# MCU_ECC_AGGR0_ECC_AGGR register map
Vendor: Texas Instruments
Peripheral module from a debugger description file (folder am65x).
Registers are 32-bit, access not given, reset 0x0 unless marked. A register's access mark holds for its fields unless they carry their own. Offsets are as the file gives them; lines under a group give offsets from that group; [hi:lo] are bit positions; {n}, {i} and the like mark numbered series; 'fields as' and 'values as' point back to an identical list; <NAME> marks a mode.

## MCU_ECC_AGGR0_ECC_AGGR
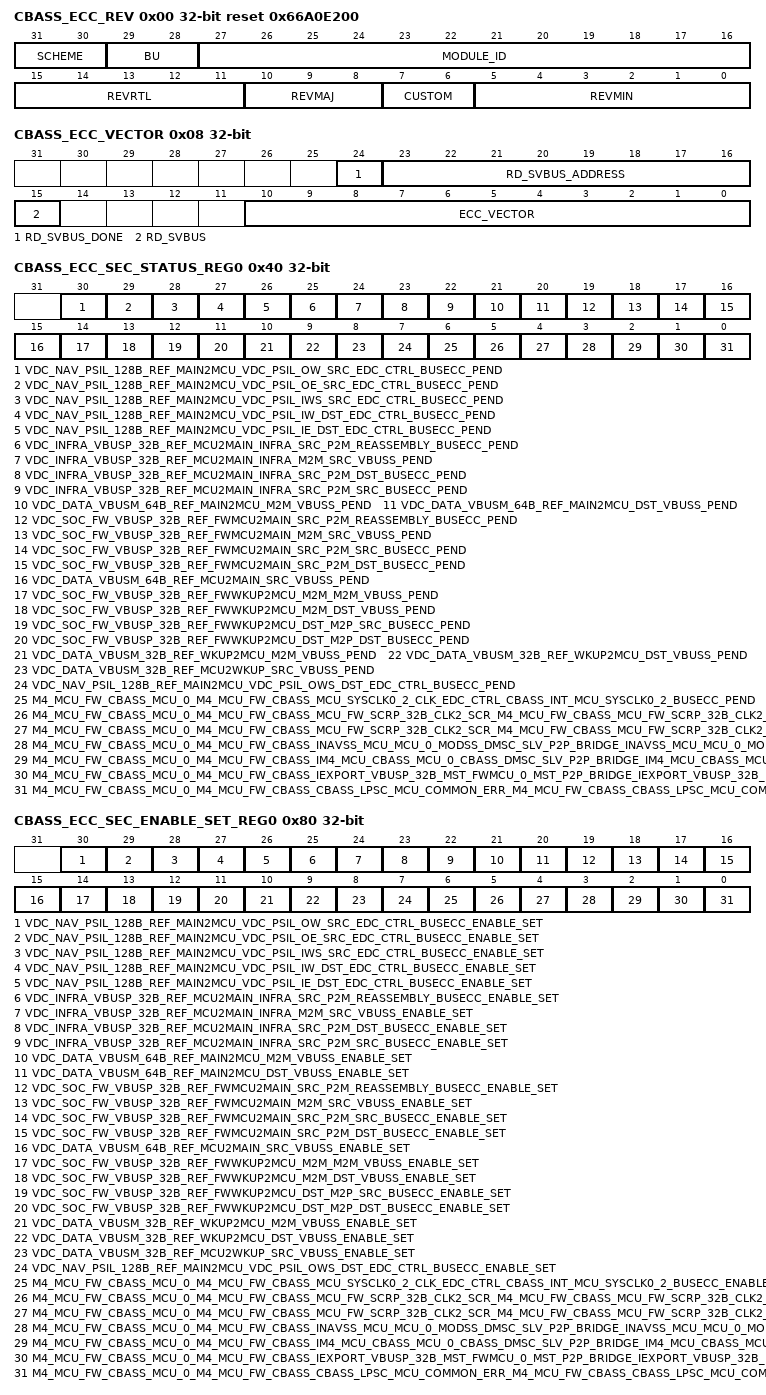
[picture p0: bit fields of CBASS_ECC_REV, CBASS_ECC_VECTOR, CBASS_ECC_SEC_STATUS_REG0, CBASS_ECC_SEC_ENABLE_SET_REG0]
0x00 CBASS_ECC_REV ro reset 0x66A0E200 — Return to the . Revision parameters
  [31:30] SCHEME
  [29:28] BU
  [27:16] MODULE_ID
  [15:11] REVRTL — RTL version
  [10:8] REVMAJ — Major version
  [7:6] CUSTOM — Custom version
  [5:0] REVMIN — Minor version
0x08 CBASS_ECC_VECTOR — Return to the . ECC Vector Register
  [24] RD_SVBUS_DONE — Status to indicate if read on serial VBUS is complete, write of any value will clear this bit. (access RW1C)
  [23:16] RD_SVBUS_ADDRESS rw — Read address
  [15] RD_SVBUS — Write 1 to trigger a read on the serial VBUS (access RW1S)
  [10:0] ECC_VECTOR rw — Value written to select the corresponding ECC RAM for control or status
0x0C CBASS_ECC_STAT ro reset 0x1F — Return to the . Misc Status
  [10:0] NUM_RAMS — Indicates the number of RAMS serviced by the ECC aggregator
0x3C CBASS_ECC_SEC_EOI_REG — Return to the . EOI Register
  [0] EOI_WR — EOI Register (access RW1S)
0x40 CBASS_ECC_SEC_STATUS_REG0 — Return to the . Interrupt Status Register 0
  [30] VDC_NAV_PSIL_128B_REF_MAIN2MCU_VDC_PSIL_OW_SRC_EDC_CTRL_BUSECC_PEND — Interrupt Pending Status for vdc_nav_psil_128b_ref_main2mcu_vdc_psil_ow_src_edc_ctrl_busecc__pend (access RW1S)
  [29] VDC_NAV_PSIL_128B_REF_MAIN2MCU_VDC_PSIL_OE_SRC_EDC_CTRL_BUSECC_PEND — Interrupt Pending Status for vdc_nav_psil_128b_ref_main2mcu_vdc_psil_oe_src_edc_ctrl_busecc__pend (access RW1S)
  [28] VDC_NAV_PSIL_128B_REF_MAIN2MCU_VDC_PSIL_IWS_SRC_EDC_CTRL_BUSECC_PEND — Interrupt Pending Status for vdc_nav_psil_128b_ref_main2mcu_vdc_psil_iws_src_edc_ctrl_busecc__pend (access RW1S)
  [27] VDC_NAV_PSIL_128B_REF_MAIN2MCU_VDC_PSIL_IW_DST_EDC_CTRL_BUSECC_PEND — Interrupt Pending Status for vdc_nav_psil_128b_ref_main2mcu_vdc_psil_iw_dst_edc_ctrl_busecc__pend (access RW1S)
  [26] VDC_NAV_PSIL_128B_REF_MAIN2MCU_VDC_PSIL_IE_DST_EDC_CTRL_BUSECC_PEND — Interrupt Pending Status for vdc_nav_psil_128b_ref_main2mcu_vdc_psil_ie_dst_edc_ctrl_busecc__pend (access RW1S)
  [25] VDC_INFRA_VBUSP_32B_REF_MCU2MAIN_INFRA_SRC_P2M_REASSEMBLY_BUSECC_PEND — Interrupt Pending Status for vdc_infra_vbusp_32b_ref_mcu2main_infra_src_p2m_reassembly_busecc__pend (access RW1S)
  [24] VDC_INFRA_VBUSP_32B_REF_MCU2MAIN_INFRA_M2M_SRC_VBUSS_PEND — Interrupt Pending Status for vdc_infra_vbusp_32b_ref_mcu2main_infra_m2m_src_vbuss__pend (access RW1S)
  [23] VDC_INFRA_VBUSP_32B_REF_MCU2MAIN_INFRA_SRC_P2M_DST_BUSECC_PEND — Interrupt Pending Status for vdc_infra_vbusp_32b_ref_mcu2main_infra_src_p2m_dst_busecc__pend (access RW1S)
  [22] VDC_INFRA_VBUSP_32B_REF_MCU2MAIN_INFRA_SRC_P2M_SRC_BUSECC_PEND — Interrupt Pending Status for vdc_infra_vbusp_32b_ref_mcu2main_infra_src_p2m_src_busecc__pend (access RW1S)
  [21] VDC_DATA_VBUSM_64B_REF_MAIN2MCU_M2M_VBUSS_PEND — Interrupt Pending Status for vdc_data_vbusm_64b_ref_main2mcu_m2m_vbuss__pend (access RW1S)
  [20] VDC_DATA_VBUSM_64B_REF_MAIN2MCU_DST_VBUSS_PEND — Interrupt Pending Status for vdc_data_vbusm_64b_ref_main2mcu_dst_vbuss__pend (access RW1S)
  [19] VDC_SOC_FW_VBUSP_32B_REF_FWMCU2MAIN_SRC_P2M_REASSEMBLY_BUSECC_PEND — Interrupt Pending Status for vdc_soc_fw_vbusp_32b_ref_fwmcu2main_src_p2m_reassembly_busecc__pend (access RW1S)
  [18] VDC_SOC_FW_VBUSP_32B_REF_FWMCU2MAIN_M2M_SRC_VBUSS_PEND — Interrupt Pending Status for vdc_soc_fw_vbusp_32b_ref_fwmcu2main_m2m_src_vbuss__pend (access RW1S)
  [17] VDC_SOC_FW_VBUSP_32B_REF_FWMCU2MAIN_SRC_P2M_SRC_BUSECC_PEND — Interrupt Pending Status for vdc_soc_fw_vbusp_32b_ref_fwmcu2main_src_p2m_src_busecc__pend (access RW1S)
  [16] VDC_SOC_FW_VBUSP_32B_REF_FWMCU2MAIN_SRC_P2M_DST_BUSECC_PEND — Interrupt Pending Status for vdc_soc_fw_vbusp_32b_ref_fwmcu2main_src_p2m_dst_busecc__pend (access RW1S)
  [15] VDC_DATA_VBUSM_64B_REF_MCU2MAIN_SRC_VBUSS_PEND — Interrupt Pending Status for vdc_data_vbusm_64b_ref_mcu2main_src_vbuss__pend (access RW1S)
  [14] VDC_SOC_FW_VBUSP_32B_REF_FWWKUP2MCU_M2M_M2M_VBUSS_PEND — Interrupt Pending Status for vdc_soc_fw_vbusp_32b_ref_fwwkup2mcu_m2m_m2m_vbuss__pend (access RW1S)
  [13] VDC_SOC_FW_VBUSP_32B_REF_FWWKUP2MCU_M2M_DST_VBUSS_PEND — Interrupt Pending Status for vdc_soc_fw_vbusp_32b_ref_fwwkup2mcu_m2m_dst_vbuss__pend (access RW1S)
  [12] VDC_SOC_FW_VBUSP_32B_REF_FWWKUP2MCU_DST_M2P_SRC_BUSECC_PEND — Interrupt Pending Status for vdc_soc_fw_vbusp_32b_ref_fwwkup2mcu_dst_m2p_src_busecc__pend (access RW1S)
  [11] VDC_SOC_FW_VBUSP_32B_REF_FWWKUP2MCU_DST_M2P_DST_BUSECC_PEND — Interrupt Pending Status for vdc_soc_fw_vbusp_32b_ref_fwwkup2mcu_dst_m2p_dst_busecc__pend (access RW1S)
  [10] VDC_DATA_VBUSM_32B_REF_WKUP2MCU_M2M_VBUSS_PEND — Interrupt Pending Status for vdc_data_vbusm_32b_ref_wkup2mcu_m2m_vbuss__pend (access RW1S)
  [9] VDC_DATA_VBUSM_32B_REF_WKUP2MCU_DST_VBUSS_PEND — Interrupt Pending Status for vdc_data_vbusm_32b_ref_wkup2mcu_dst_vbuss__pend (access RW1S)
  [8] VDC_DATA_VBUSM_32B_REF_MCU2WKUP_SRC_VBUSS_PEND — Interrupt Pending Status for vdc_data_vbusm_32b_ref_mcu2wkup_src_vbuss__pend (access RW1S)
  [7] VDC_NAV_PSIL_128B_REF_MAIN2MCU_VDC_PSIL_OWS_DST_EDC_CTRL_BUSECC_PEND — Interrupt Pending Status for vdc_nav_psil_128b_ref_main2mcu_vdc_psil_ows_dst_edc_ctrl_busecc__pend (access RW1S)
  [6] M4_MCU_FW_CBASS_MCU_0_M4_MCU_FW_CBASS_MCU_SYSCLK0_2_CLK_EDC_CTRL_CBASS_INT_MCU_SYSCLK0_2_BUSECC_PEND — Interrupt Pending Status for m4_mcu_fw_cbass_mcu_0_m4_mcu_fw_cbass_mcu_sysclk0_2_clk_edc_ctrl_cbass_int_mcu_sysclk0_2_busecc__pend (access RW1S)
  [5] M4_MCU_FW_CBASS_MCU_0_M4_MCU_FW_CBASS_MCU_FW_SCRP_32B_CLK2_SCR_M4_MCU_FW_CBASS_MCU_FW_SCRP_32B_CLK2_SCR_EDC_CTRL_BUSECC_1_PEND — Interrupt Pending Status for m4_mcu_fw_cbass_mcu_0_m4_mcu_fw_cbass_MCU_FW_SCRP_32b_CLK2_scr_m4_mcu_fw_cbass_MCU_FW_SCRP_32b_CLK2_scr_edc_ctrl_busecc_1__pend (access RW1S)
  [4] M4_MCU_FW_CBASS_MCU_0_M4_MCU_FW_CBASS_MCU_FW_SCRP_32B_CLK2_SCR_M4_MCU_FW_CBASS_MCU_FW_SCRP_32B_CLK2_SCR_EDC_CTRL_BUSECC_0_PEND — Interrupt Pending Status for m4_mcu_fw_cbass_mcu_0_m4_mcu_fw_cbass_MCU_FW_SCRP_32b_CLK2_scr_m4_mcu_fw_cbass_MCU_FW_SCRP_32b_CLK2_scr_edc_ctrl_busecc_0__pend (access RW1S)
  [3] M4_MCU_FW_CBASS_MCU_0_M4_MCU_FW_CBASS_INAVSS_MCU_MCU_0_MODSS_DMSC_SLV_P2P_BRIDGE_INAVSS_MCU_MCU_0_MODSS_DMSC_SLV_BRIDGE_BUSECC_PEND — Interrupt Pending Status for m4_mcu_fw_cbass_mcu_0_m4_mcu_fw_cbass_Inavss_mcu_mcu_0_modss_dmsc_slv_p2p_bridge_Inavss_mcu_mcu_0_modss_dmsc_slv_bridge_busecc__pend (access RW1S)
  [2] M4_MCU_FW_CBASS_MCU_0_M4_MCU_FW_CBASS_IM4_MCU_CBASS_MCU_0_CBASS_DMSC_SLV_P2P_BRIDGE_IM4_MCU_CBASS_MCU_0_CBASS_DMSC_SLV_BRIDGE_BUSECC_PEND — Interrupt Pending Status for m4_mcu_fw_cbass_mcu_0_m4_mcu_fw_cbass_Im4_mcu_cbass_mcu_0_cbass_dmsc_slv_p2p_bridge_Im4_mcu_cbass_mcu_0_cbass_dmsc_slv_bridge_busecc__pend (access RW1S)
  [1] M4_MCU_FW_CBASS_MCU_0_M4_MCU_FW_CBASS_IEXPORT_VBUSP_32B_MST_FWMCU_0_MST_P2P_BRIDGE_IEXPORT_VBUSP_32B_MST_FWMCU_0_MST_BRIDGE_BUSECC_PEND — Interrupt Pending Status for m4_mcu_fw_cbass_mcu_0_m4_mcu_fw_cbass_Iexport_vbusp_32b_mst_fwmcu_0_mst_p2p_bridge_Iexport_vbusp_32b_mst_fwmcu_0_mst_bridge_busecc__pend (access RW1S)
  [0] M4_MCU_FW_CBASS_MCU_0_M4_MCU_FW_CBASS_CBASS_LPSC_MCU_COMMON_ERR_M4_MCU_FW_CBASS_CBASS_LPSC_MCU_COMMON_ERR_EDC_CTRL_BUSECC_PEND — Interrupt Pending Status for m4_mcu_fw_cbass_mcu_0_m4_mcu_fw_cbass_cbass_LPSC_MCU_common_err_m4_mcu_fw_cbass_cbass_LPSC_MCU_common_err_edc_ctrl_busecc__pend (access RW1S)
0x80 CBASS_ECC_SEC_ENABLE_SET_REG0 — Return to the . Interrupt Enable Set Register 0
  [30] VDC_NAV_PSIL_128B_REF_MAIN2MCU_VDC_PSIL_OW_SRC_EDC_CTRL_BUSECC_ENABLE_SET — Interrupt Enable Set Register for vdc_nav_psil_128b_ref_main2mcu_vdc_psil_ow_src_edc_ctrl_busecc__pend (access RW1S)
  [29] VDC_NAV_PSIL_128B_REF_MAIN2MCU_VDC_PSIL_OE_SRC_EDC_CTRL_BUSECC_ENABLE_SET — Interrupt Enable Set Register for vdc_nav_psil_128b_ref_main2mcu_vdc_psil_oe_src_edc_ctrl_busecc__pend (access RW1S)
  [28] VDC_NAV_PSIL_128B_REF_MAIN2MCU_VDC_PSIL_IWS_SRC_EDC_CTRL_BUSECC_ENABLE_SET — Interrupt Enable Set Register for vdc_nav_psil_128b_ref_main2mcu_vdc_psil_iws_src_edc_ctrl_busecc__pend (access RW1S)
  [27] VDC_NAV_PSIL_128B_REF_MAIN2MCU_VDC_PSIL_IW_DST_EDC_CTRL_BUSECC_ENABLE_SET — Interrupt Enable Set Register for vdc_nav_psil_128b_ref_main2mcu_vdc_psil_iw_dst_edc_ctrl_busecc__pend (access RW1S)
  [26] VDC_NAV_PSIL_128B_REF_MAIN2MCU_VDC_PSIL_IE_DST_EDC_CTRL_BUSECC_ENABLE_SET — Interrupt Enable Set Register for vdc_nav_psil_128b_ref_main2mcu_vdc_psil_ie_dst_edc_ctrl_busecc__pend (access RW1S)
  [25] VDC_INFRA_VBUSP_32B_REF_MCU2MAIN_INFRA_SRC_P2M_REASSEMBLY_BUSECC_ENABLE_SET — Interrupt Enable Set Register for vdc_infra_vbusp_32b_ref_mcu2main_infra_src_p2m_reassembly_busecc__pend (access RW1S)
  [24] VDC_INFRA_VBUSP_32B_REF_MCU2MAIN_INFRA_M2M_SRC_VBUSS_ENABLE_SET — Interrupt Enable Set Register for vdc_infra_vbusp_32b_ref_mcu2main_infra_m2m_src_vbuss__pend (access RW1S)
  [23] VDC_INFRA_VBUSP_32B_REF_MCU2MAIN_INFRA_SRC_P2M_DST_BUSECC_ENABLE_SET — Interrupt Enable Set Register for vdc_infra_vbusp_32b_ref_mcu2main_infra_src_p2m_dst_busecc__pend (access RW1S)
  [22] VDC_INFRA_VBUSP_32B_REF_MCU2MAIN_INFRA_SRC_P2M_SRC_BUSECC_ENABLE_SET — Interrupt Enable Set Register for vdc_infra_vbusp_32b_ref_mcu2main_infra_src_p2m_src_busecc__pend (access RW1S)
  [21] VDC_DATA_VBUSM_64B_REF_MAIN2MCU_M2M_VBUSS_ENABLE_SET — Interrupt Enable Set Register for vdc_data_vbusm_64b_ref_main2mcu_m2m_vbuss__pend (access RW1S)
  [20] VDC_DATA_VBUSM_64B_REF_MAIN2MCU_DST_VBUSS_ENABLE_SET — Interrupt Enable Set Register for vdc_data_vbusm_64b_ref_main2mcu_dst_vbuss__pend (access RW1S)
  [19] VDC_SOC_FW_VBUSP_32B_REF_FWMCU2MAIN_SRC_P2M_REASSEMBLY_BUSECC_ENABLE_SET — Interrupt Enable Set Register for vdc_soc_fw_vbusp_32b_ref_fwmcu2main_src_p2m_reassembly_busecc__pend (access RW1S)
  [18] VDC_SOC_FW_VBUSP_32B_REF_FWMCU2MAIN_M2M_SRC_VBUSS_ENABLE_SET — Interrupt Enable Set Register for vdc_soc_fw_vbusp_32b_ref_fwmcu2main_m2m_src_vbuss__pend (access RW1S)
  [17] VDC_SOC_FW_VBUSP_32B_REF_FWMCU2MAIN_SRC_P2M_SRC_BUSECC_ENABLE_SET — Interrupt Enable Set Register for vdc_soc_fw_vbusp_32b_ref_fwmcu2main_src_p2m_src_busecc__pend (access RW1S)
  [16] VDC_SOC_FW_VBUSP_32B_REF_FWMCU2MAIN_SRC_P2M_DST_BUSECC_ENABLE_SET — Interrupt Enable Set Register for vdc_soc_fw_vbusp_32b_ref_fwmcu2main_src_p2m_dst_busecc__pend (access RW1S)
  [15] VDC_DATA_VBUSM_64B_REF_MCU2MAIN_SRC_VBUSS_ENABLE_SET — Interrupt Enable Set Register for vdc_data_vbusm_64b_ref_mcu2main_src_vbuss__pend (access RW1S)
  [14] VDC_SOC_FW_VBUSP_32B_REF_FWWKUP2MCU_M2M_M2M_VBUSS_ENABLE_SET — Interrupt Enable Set Register for vdc_soc_fw_vbusp_32b_ref_fwwkup2mcu_m2m_m2m_vbuss__pend (access RW1S)
  [13] VDC_SOC_FW_VBUSP_32B_REF_FWWKUP2MCU_M2M_DST_VBUSS_ENABLE_SET — Interrupt Enable Set Register for vdc_soc_fw_vbusp_32b_ref_fwwkup2mcu_m2m_dst_vbuss__pend (access RW1S)
  [12] VDC_SOC_FW_VBUSP_32B_REF_FWWKUP2MCU_DST_M2P_SRC_BUSECC_ENABLE_SET — Interrupt Enable Set Register for vdc_soc_fw_vbusp_32b_ref_fwwkup2mcu_dst_m2p_src_busecc__pend (access RW1S)
  [11] VDC_SOC_FW_VBUSP_32B_REF_FWWKUP2MCU_DST_M2P_DST_BUSECC_ENABLE_SET — Interrupt Enable Set Register for vdc_soc_fw_vbusp_32b_ref_fwwkup2mcu_dst_m2p_dst_busecc__pend (access RW1S)
  [10] VDC_DATA_VBUSM_32B_REF_WKUP2MCU_M2M_VBUSS_ENABLE_SET — Interrupt Enable Set Register for vdc_data_vbusm_32b_ref_wkup2mcu_m2m_vbuss__pend (access RW1S)
  [9] VDC_DATA_VBUSM_32B_REF_WKUP2MCU_DST_VBUSS_ENABLE_SET — Interrupt Enable Set Register for vdc_data_vbusm_32b_ref_wkup2mcu_dst_vbuss__pend (access RW1S)
  [8] VDC_DATA_VBUSM_32B_REF_MCU2WKUP_SRC_VBUSS_ENABLE_SET — Interrupt Enable Set Register for vdc_data_vbusm_32b_ref_mcu2wkup_src_vbuss__pend (access RW1S)
  [7] VDC_NAV_PSIL_128B_REF_MAIN2MCU_VDC_PSIL_OWS_DST_EDC_CTRL_BUSECC_ENABLE_SET — Interrupt Enable Set Register for vdc_nav_psil_128b_ref_main2mcu_vdc_psil_ows_dst_edc_ctrl_busecc__pend (access RW1S)
  [6] M4_MCU_FW_CBASS_MCU_0_M4_MCU_FW_CBASS_MCU_SYSCLK0_2_CLK_EDC_CTRL_CBASS_INT_MCU_SYSCLK0_2_BUSECC_ENABLE_SET — Interrupt Enable Set Register for m4_mcu_fw_cbass_mcu_0_m4_mcu_fw_cbass_mcu_sysclk0_2_clk_edc_ctrl_cbass_int_mcu_sysclk0_2_busecc__pend (access RW1S)
  [5] M4_MCU_FW_CBASS_MCU_0_M4_MCU_FW_CBASS_MCU_FW_SCRP_32B_CLK2_SCR_M4_MCU_FW_CBASS_MCU_FW_SCRP_32B_CLK2_SCR_EDC_CTRL_BUSECC_1_ENABLE_SET — Interrupt Enable Set Register for m4_mcu_fw_cbass_mcu_0_m4_mcu_fw_cbass_MCU_FW_SCRP_32b_CLK2_scr_m4_mcu_fw_cbass_MCU_FW_SCRP_32b_CLK2_scr_edc_ctrl_busecc_1__pend (access RW1S)
  [4] M4_MCU_FW_CBASS_MCU_0_M4_MCU_FW_CBASS_MCU_FW_SCRP_32B_CLK2_SCR_M4_MCU_FW_CBASS_MCU_FW_SCRP_32B_CLK2_SCR_EDC_CTRL_BUSECC_0_ENABLE_SET — Interrupt Enable Set Register for m4_mcu_fw_cbass_mcu_0_m4_mcu_fw_cbass_MCU_FW_SCRP_32b_CLK2_scr_m4_mcu_fw_cbass_MCU_FW_SCRP_32b_CLK2_scr_edc_ctrl_busecc_0__pend (access RW1S)
  [3] M4_MCU_FW_CBASS_MCU_0_M4_MCU_FW_CBASS_INAVSS_MCU_MCU_0_MODSS_DMSC_SLV_P2P_BRIDGE_INAVSS_MCU_MCU_0_MODSS_DMSC_SLV_BRIDGE_BUSECC_ENABLE_SET — Interrupt Enable Set Register for m4_mcu_fw_cbass_mcu_0_m4_mcu_fw_cbass_Inavss_mcu_mcu_0_modss_dmsc_slv_p2p_bridge_Inavss_mcu_mcu_0_modss_dmsc_slv_bridge_busecc__pend (access RW1S)
  [2] M4_MCU_FW_CBASS_MCU_0_M4_MCU_FW_CBASS_IM4_MCU_CBASS_MCU_0_CBASS_DMSC_SLV_P2P_BRIDGE_IM4_MCU_CBASS_MCU_0_CBASS_DMSC_SLV_BRIDGE_BUSECC_ENABLE_SET — Interrupt Enable Set Register for m4_mcu_fw_cbass_mcu_0_m4_mcu_fw_cbass_Im4_mcu_cbass_mcu_0_cbass_dmsc_slv_p2p_bridge_Im4_mcu_cbass_mcu_0_cbass_dmsc_slv_bridge_busecc__pend (access RW1S)
  [1] M4_MCU_FW_CBASS_MCU_0_M4_MCU_FW_CBASS_IEXPORT_VBUSP_32B_MST_FWMCU_0_MST_P2P_BRIDGE_IEXPORT_VBUSP_32B_MST_FWMCU_0_MST_BRIDGE_BUSECC_ENABLE_SET — Interrupt Enable Set Register for m4_mcu_fw_cbass_mcu_0_m4_mcu_fw_cbass_Iexport_vbusp_32b_mst_fwmcu_0_mst_p2p_bridge_Iexport_vbusp_32b_mst_fwmcu_0_mst_bridge_busecc__pend (access RW1S)
  [0] M4_MCU_FW_CBASS_MCU_0_M4_MCU_FW_CBASS_CBASS_LPSC_MCU_COMMON_ERR_M4_MCU_FW_CBASS_CBASS_LPSC_MCU_COMMON_ERR_EDC_CTRL_BUSECC_ENABLE_SET — Interrupt Enable Set Register for m4_mcu_fw_cbass_mcu_0_m4_mcu_fw_cbass_cbass_LPSC_MCU_common_err_m4_mcu_fw_cbass_cbass_LPSC_MCU_common_err_edc_ctrl_busecc__pend (access RW1S)
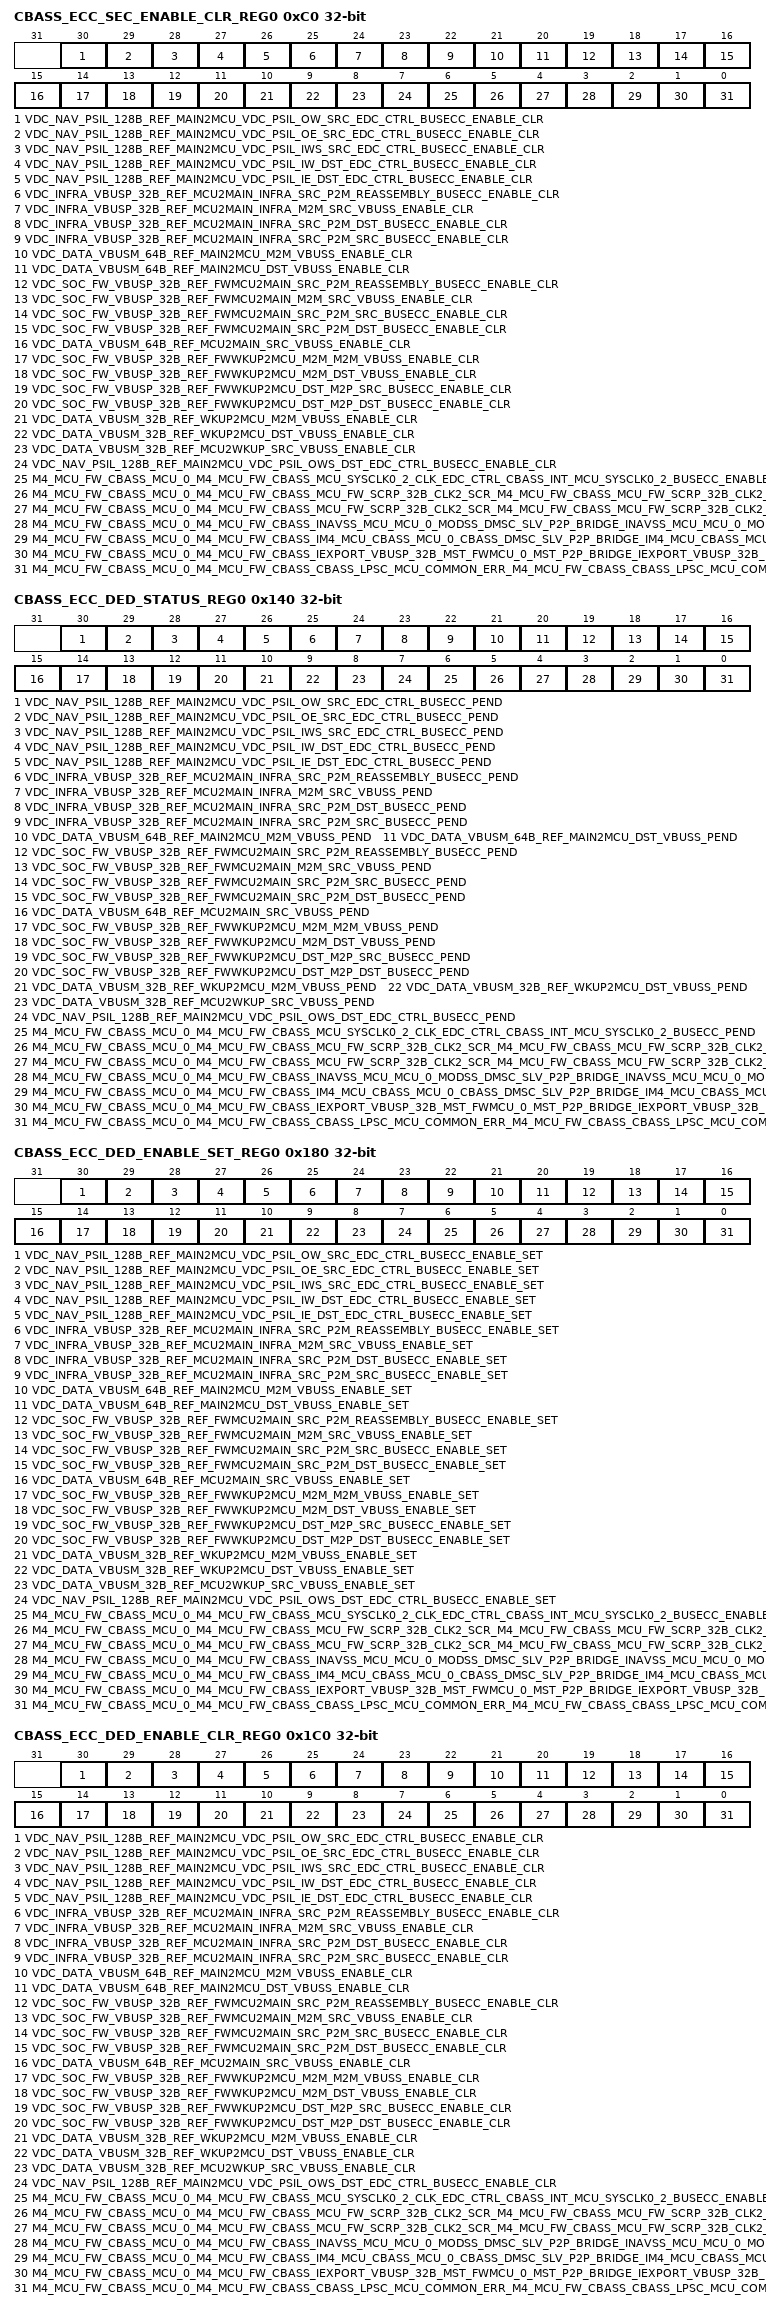
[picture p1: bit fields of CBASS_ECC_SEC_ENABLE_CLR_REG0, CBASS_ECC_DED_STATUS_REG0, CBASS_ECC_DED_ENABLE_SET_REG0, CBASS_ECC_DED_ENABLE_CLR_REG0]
0xC0 CBASS_ECC_SEC_ENABLE_CLR_REG0 — Return to the . Interrupt Enable Clear Register 0
  [30] VDC_NAV_PSIL_128B_REF_MAIN2MCU_VDC_PSIL_OW_SRC_EDC_CTRL_BUSECC_ENABLE_CLR — Interrupt Enable Clear Register for vdc_nav_psil_128b_ref_main2mcu_vdc_psil_ow_src_edc_ctrl_busecc__pend (access RW1C)
  [29] VDC_NAV_PSIL_128B_REF_MAIN2MCU_VDC_PSIL_OE_SRC_EDC_CTRL_BUSECC_ENABLE_CLR — Interrupt Enable Clear Register for vdc_nav_psil_128b_ref_main2mcu_vdc_psil_oe_src_edc_ctrl_busecc__pend (access RW1C)
  [28] VDC_NAV_PSIL_128B_REF_MAIN2MCU_VDC_PSIL_IWS_SRC_EDC_CTRL_BUSECC_ENABLE_CLR — Interrupt Enable Clear Register for vdc_nav_psil_128b_ref_main2mcu_vdc_psil_iws_src_edc_ctrl_busecc__pend (access RW1C)
  [27] VDC_NAV_PSIL_128B_REF_MAIN2MCU_VDC_PSIL_IW_DST_EDC_CTRL_BUSECC_ENABLE_CLR — Interrupt Enable Clear Register for vdc_nav_psil_128b_ref_main2mcu_vdc_psil_iw_dst_edc_ctrl_busecc__pend (access RW1C)
  [26] VDC_NAV_PSIL_128B_REF_MAIN2MCU_VDC_PSIL_IE_DST_EDC_CTRL_BUSECC_ENABLE_CLR — Interrupt Enable Clear Register for vdc_nav_psil_128b_ref_main2mcu_vdc_psil_ie_dst_edc_ctrl_busecc__pend (access RW1C)
  [25] VDC_INFRA_VBUSP_32B_REF_MCU2MAIN_INFRA_SRC_P2M_REASSEMBLY_BUSECC_ENABLE_CLR — Interrupt Enable Clear Register for vdc_infra_vbusp_32b_ref_mcu2main_infra_src_p2m_reassembly_busecc__pend (access RW1C)
  [24] VDC_INFRA_VBUSP_32B_REF_MCU2MAIN_INFRA_M2M_SRC_VBUSS_ENABLE_CLR — Interrupt Enable Clear Register for vdc_infra_vbusp_32b_ref_mcu2main_infra_m2m_src_vbuss__pend (access RW1C)
  [23] VDC_INFRA_VBUSP_32B_REF_MCU2MAIN_INFRA_SRC_P2M_DST_BUSECC_ENABLE_CLR — Interrupt Enable Clear Register for vdc_infra_vbusp_32b_ref_mcu2main_infra_src_p2m_dst_busecc__pend (access RW1C)
  [22] VDC_INFRA_VBUSP_32B_REF_MCU2MAIN_INFRA_SRC_P2M_SRC_BUSECC_ENABLE_CLR — Interrupt Enable Clear Register for vdc_infra_vbusp_32b_ref_mcu2main_infra_src_p2m_src_busecc__pend (access RW1C)
  [21] VDC_DATA_VBUSM_64B_REF_MAIN2MCU_M2M_VBUSS_ENABLE_CLR — Interrupt Enable Clear Register for vdc_data_vbusm_64b_ref_main2mcu_m2m_vbuss__pend (access RW1C)
  [20] VDC_DATA_VBUSM_64B_REF_MAIN2MCU_DST_VBUSS_ENABLE_CLR — Interrupt Enable Clear Register for vdc_data_vbusm_64b_ref_main2mcu_dst_vbuss__pend (access RW1C)
  [19] VDC_SOC_FW_VBUSP_32B_REF_FWMCU2MAIN_SRC_P2M_REASSEMBLY_BUSECC_ENABLE_CLR — Interrupt Enable Clear Register for vdc_soc_fw_vbusp_32b_ref_fwmcu2main_src_p2m_reassembly_busecc__pend (access RW1C)
  [18] VDC_SOC_FW_VBUSP_32B_REF_FWMCU2MAIN_M2M_SRC_VBUSS_ENABLE_CLR — Interrupt Enable Clear Register for vdc_soc_fw_vbusp_32b_ref_fwmcu2main_m2m_src_vbuss__pend (access RW1C)
  [17] VDC_SOC_FW_VBUSP_32B_REF_FWMCU2MAIN_SRC_P2M_SRC_BUSECC_ENABLE_CLR — Interrupt Enable Clear Register for vdc_soc_fw_vbusp_32b_ref_fwmcu2main_src_p2m_src_busecc__pend (access RW1C)
  [16] VDC_SOC_FW_VBUSP_32B_REF_FWMCU2MAIN_SRC_P2M_DST_BUSECC_ENABLE_CLR — Interrupt Enable Clear Register for vdc_soc_fw_vbusp_32b_ref_fwmcu2main_src_p2m_dst_busecc__pend (access RW1C)
  [15] VDC_DATA_VBUSM_64B_REF_MCU2MAIN_SRC_VBUSS_ENABLE_CLR — Interrupt Enable Clear Register for vdc_data_vbusm_64b_ref_mcu2main_src_vbuss__pend (access RW1C)
  [14] VDC_SOC_FW_VBUSP_32B_REF_FWWKUP2MCU_M2M_M2M_VBUSS_ENABLE_CLR — Interrupt Enable Clear Register for vdc_soc_fw_vbusp_32b_ref_fwwkup2mcu_m2m_m2m_vbuss__pend (access RW1C)
  [13] VDC_SOC_FW_VBUSP_32B_REF_FWWKUP2MCU_M2M_DST_VBUSS_ENABLE_CLR — Interrupt Enable Clear Register for vdc_soc_fw_vbusp_32b_ref_fwwkup2mcu_m2m_dst_vbuss__pend (access RW1C)
  [12] VDC_SOC_FW_VBUSP_32B_REF_FWWKUP2MCU_DST_M2P_SRC_BUSECC_ENABLE_CLR — Interrupt Enable Clear Register for vdc_soc_fw_vbusp_32b_ref_fwwkup2mcu_dst_m2p_src_busecc__pend (access RW1C)
  [11] VDC_SOC_FW_VBUSP_32B_REF_FWWKUP2MCU_DST_M2P_DST_BUSECC_ENABLE_CLR — Interrupt Enable Clear Register for vdc_soc_fw_vbusp_32b_ref_fwwkup2mcu_dst_m2p_dst_busecc__pend (access RW1C)
  [10] VDC_DATA_VBUSM_32B_REF_WKUP2MCU_M2M_VBUSS_ENABLE_CLR — Interrupt Enable Clear Register for vdc_data_vbusm_32b_ref_wkup2mcu_m2m_vbuss__pend (access RW1C)
  [9] VDC_DATA_VBUSM_32B_REF_WKUP2MCU_DST_VBUSS_ENABLE_CLR — Interrupt Enable Clear Register for vdc_data_vbusm_32b_ref_wkup2mcu_dst_vbuss__pend (access RW1C)
  [8] VDC_DATA_VBUSM_32B_REF_MCU2WKUP_SRC_VBUSS_ENABLE_CLR — Interrupt Enable Clear Register for vdc_data_vbusm_32b_ref_mcu2wkup_src_vbuss__pend (access RW1C)
  [7] VDC_NAV_PSIL_128B_REF_MAIN2MCU_VDC_PSIL_OWS_DST_EDC_CTRL_BUSECC_ENABLE_CLR — Interrupt Enable Clear Register for vdc_nav_psil_128b_ref_main2mcu_vdc_psil_ows_dst_edc_ctrl_busecc__pend (access RW1C)
  [6] M4_MCU_FW_CBASS_MCU_0_M4_MCU_FW_CBASS_MCU_SYSCLK0_2_CLK_EDC_CTRL_CBASS_INT_MCU_SYSCLK0_2_BUSECC_ENABLE_CLR — Interrupt Enable Clear Register for m4_mcu_fw_cbass_mcu_0_m4_mcu_fw_cbass_mcu_sysclk0_2_clk_edc_ctrl_cbass_int_mcu_sysclk0_2_busecc__pend (access RW1C)
  [5] M4_MCU_FW_CBASS_MCU_0_M4_MCU_FW_CBASS_MCU_FW_SCRP_32B_CLK2_SCR_M4_MCU_FW_CBASS_MCU_FW_SCRP_32B_CLK2_SCR_EDC_CTRL_BUSECC_1_ENABLE_CLR — Interrupt Enable Clear Register for m4_mcu_fw_cbass_mcu_0_m4_mcu_fw_cbass_MCU_FW_SCRP_32b_CLK2_scr_m4_mcu_fw_cbass_MCU_FW_SCRP_32b_CLK2_scr_edc_ctrl_busecc_1__pend (access RW1C)
  [4] M4_MCU_FW_CBASS_MCU_0_M4_MCU_FW_CBASS_MCU_FW_SCRP_32B_CLK2_SCR_M4_MCU_FW_CBASS_MCU_FW_SCRP_32B_CLK2_SCR_EDC_CTRL_BUSECC_0_ENABLE_CLR — Interrupt Enable Clear Register for m4_mcu_fw_cbass_mcu_0_m4_mcu_fw_cbass_MCU_FW_SCRP_32b_CLK2_scr_m4_mcu_fw_cbass_MCU_FW_SCRP_32b_CLK2_scr_edc_ctrl_busecc_0__pend (access RW1C)
  [3] M4_MCU_FW_CBASS_MCU_0_M4_MCU_FW_CBASS_INAVSS_MCU_MCU_0_MODSS_DMSC_SLV_P2P_BRIDGE_INAVSS_MCU_MCU_0_MODSS_DMSC_SLV_BRIDGE_BUSECC_ENABLE_CLR — Interrupt Enable Clear Register for m4_mcu_fw_cbass_mcu_0_m4_mcu_fw_cbass_Inavss_mcu_mcu_0_modss_dmsc_slv_p2p_bridge_Inavss_mcu_mcu_0_modss_dmsc_slv_bridge_busecc__pend (access RW1C)
  [2] M4_MCU_FW_CBASS_MCU_0_M4_MCU_FW_CBASS_IM4_MCU_CBASS_MCU_0_CBASS_DMSC_SLV_P2P_BRIDGE_IM4_MCU_CBASS_MCU_0_CBASS_DMSC_SLV_BRIDGE_BUSECC_ENABLE_CLR — Interrupt Enable Clear Register for m4_mcu_fw_cbass_mcu_0_m4_mcu_fw_cbass_Im4_mcu_cbass_mcu_0_cbass_dmsc_slv_p2p_bridge_Im4_mcu_cbass_mcu_0_cbass_dmsc_slv_bridge_busecc__pend (access RW1C)
  [1] M4_MCU_FW_CBASS_MCU_0_M4_MCU_FW_CBASS_IEXPORT_VBUSP_32B_MST_FWMCU_0_MST_P2P_BRIDGE_IEXPORT_VBUSP_32B_MST_FWMCU_0_MST_BRIDGE_BUSECC_ENABLE_CLR — Interrupt Enable Clear Register for m4_mcu_fw_cbass_mcu_0_m4_mcu_fw_cbass_Iexport_vbusp_32b_mst_fwmcu_0_mst_p2p_bridge_Iexport_vbusp_32b_mst_fwmcu_0_mst_bridge_busecc__pend (access RW1C)
  [0] M4_MCU_FW_CBASS_MCU_0_M4_MCU_FW_CBASS_CBASS_LPSC_MCU_COMMON_ERR_M4_MCU_FW_CBASS_CBASS_LPSC_MCU_COMMON_ERR_EDC_CTRL_BUSECC_ENABLE_CLR — Interrupt Enable Clear Register for m4_mcu_fw_cbass_mcu_0_m4_mcu_fw_cbass_cbass_LPSC_MCU_common_err_m4_mcu_fw_cbass_cbass_LPSC_MCU_common_err_edc_ctrl_busecc__pend (access RW1C)
0x13C CBASS_ECC_DED_EOI_REG — Return to the . EOI Register
  [0] EOI_WR — EOI Register (access RW1S)
0x140 CBASS_ECC_DED_STATUS_REG0 — Return to the . Interrupt Status Register 0
  fields as CBASS_ECC_SEC_STATUS_REG0
0x180 CBASS_ECC_DED_ENABLE_SET_REG0 — Return to the . Interrupt Enable Set Register 0
  fields as CBASS_ECC_SEC_ENABLE_SET_REG0
0x1C0 CBASS_ECC_DED_ENABLE_CLR_REG0 — Return to the . Interrupt Enable Clear Register 0
  fields as CBASS_ECC_SEC_ENABLE_CLR_REG0
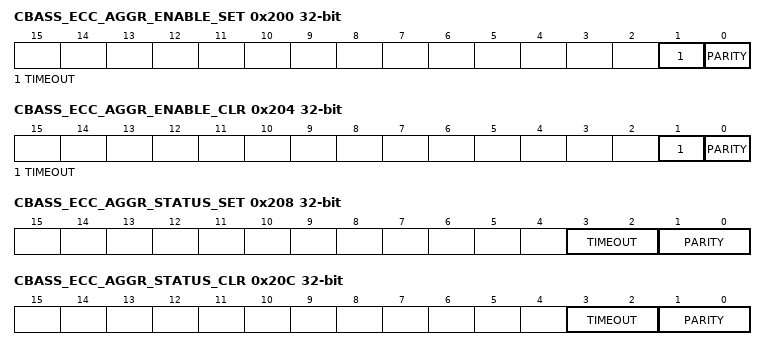
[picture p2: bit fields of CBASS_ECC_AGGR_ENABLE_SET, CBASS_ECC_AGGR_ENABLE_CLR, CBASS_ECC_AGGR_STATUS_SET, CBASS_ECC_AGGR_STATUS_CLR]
0x200 CBASS_ECC_AGGR_ENABLE_SET — Return to the . AGGR interrupt enable set Register
  [1] TIMEOUT — interrupt enable set for svbus timeout errors (access RW1S)
  [0] PARITY — interrupt enable set for parity errors (access RW1S)
0x204 CBASS_ECC_AGGR_ENABLE_CLR — Return to the . AGGR interrupt enable clear Register
  [1] TIMEOUT — interrupt enable clear for svbus timeout errors (access RW1C)
  [0] PARITY — interrupt enable clear for parity errors (access RW1C)
0x208 CBASS_ECC_AGGR_STATUS_SET rw — Return to the . AGGR interrupt status set Register
  [3:2] TIMEOUT — interrupt status set for svbus timeout errors
  [1:0] PARITY — interrupt status set for parity errors
0x20C CBASS_ECC_AGGR_STATUS_CLR rw — Return to the . AGGR interrupt status clear Register
  [3:2] TIMEOUT — interrupt status clear for svbus timeout errors
  [1:0] PARITY — interrupt status clear for parity errors
